# MSS_PKA register map
Vendor: Texas Instruments
Peripheral module from a debugger description file (folder radar).
Registers are 32-bit, access per field, no defined reset value unless marked. A register's access mark holds for its fields unless they carry their own. Offsets are as the file gives them; lines under a group give offsets from that group; [hi:lo] are bit positions; {n}, {i} and the like mark numbered series; 'fields as' and 'values as' point back to an identical list; <NAME> marks a mode.

## MSS_PKA
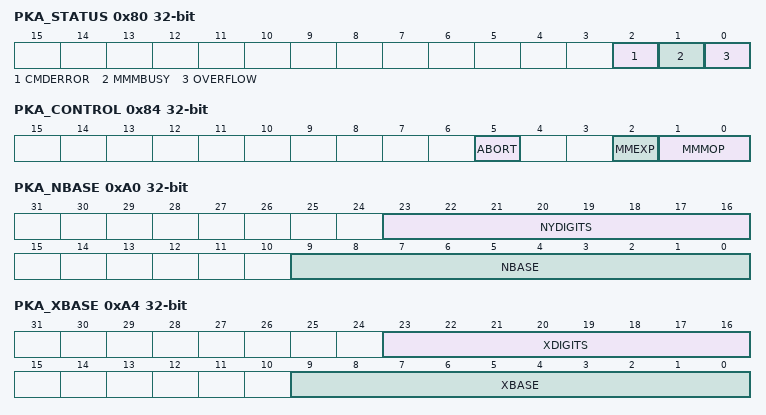
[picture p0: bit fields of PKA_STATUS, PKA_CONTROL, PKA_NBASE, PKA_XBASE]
0x80 PKA_STATUS
  [2] CMDERROR rw — Set to ‘1’ by pkaeip29t when trying to start multiple operations in one command automatically cleared to ‘0’ by hardware on start of any (legal) operation.
  [1] MMMBUSY rw — Set to ‘1’ by pkaeip29t when the LNME executes an MMM MMMNEXT MMM3A or MMEXP operation (cannot be written to ‘0’ during execution of this operation). Automatically cleared to ‘0’ by pkaeip29t on finish of an operation. The interrupt output is the complement of this bit and can be controlled directly for testing purposes when no actual operation is busy.
  [0] OVERFLOW rw — Set to ‘1’ by pkaeip29t when the result of MMM MMMNEXT MMM3A or MMEXP operation is equal or greater than the modulus N. Updated at the end of an operation automatically cleared to ‘0’ by pkaeip29t on start of any operation.
0x84 PKA_CONTROL
  [5] ABORT rw — Set to ‘1’ the pkaeip29t is reset and all internal storage locations are flushed within 200 clock cycles is cleared to ‘0’ by hardware at the end of the operation. This command has priority over the MMM MMMNEXT MMM3A and MMEXP commands and can abort those in mid-execution. 0 No operation 1 abort
  [2] MMEXP rw — The pkaeip29t starts an MMEXP operation bit is cleared to ‘0’ by pkaeip29t at the end of the operation or when executing an ABORT command. 0 No operation. 1 Starts an MMEXP operation.
  [1:0] MMMOP rw — When set to a non-zero value the pkaeip29t starts an MMM operation cleared to ‘00’ by hardware at the end of the operation or when executing an ABORT command: 0x0 No operation 0x1 Starts a basic MMM operation (result written over the Y operand vector) 0x2 Starts an MMMNEXT operation (result written following the Y operand) 0x3 Starts an MMM3A operation (result written at the B operand address)
0xA0 PKA_NBASE
  [23:16] NYDIGITS rw — Y-Operand and N-Operand 32-bit Digits. Also used for X-operand length in an MMEXP operation. Minimum value is 0 (for 32-bit operands) maximum value is 66 (for 2112-bit operands actually 2112 ‘real’ data bits plus 32 bits to handle inputs and results higher than the 2112 bits modulus value).
  [9:0] NBASE rw — N-Operand Base Address. Bit [0] is forced to ‘0’ to locate the first 32-bit word at a 64-bit word boundary.
0xA4 PKA_XBASE
  [23:16] XDIGITS rw — X-Operand 32-bit Digits used for MMM MMMNEXT and MMM3A operations only. Minimum value is 0 (for 32-bit X operands) maximum value is 66 (for 2114-bit X operands actually 2112 ‘real’ data bits plus 2 extra bits to handle X inputs up to four times the 2112-bit modulus value plus 30 dummy data bits to fill out the last word which should all be 0).
  [9:0] XBASE rw — X-Operand Base Address. Bit [0] is forced to ‘0’ to locate the first 32-bit word at a 64-bit word boundary.
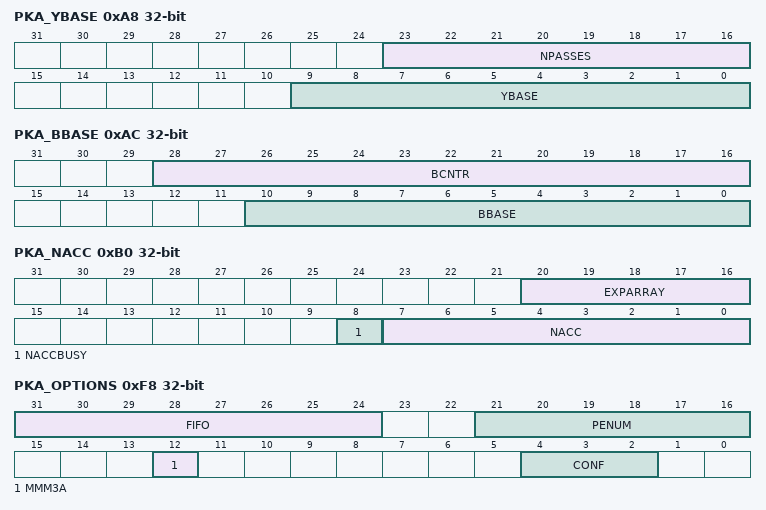
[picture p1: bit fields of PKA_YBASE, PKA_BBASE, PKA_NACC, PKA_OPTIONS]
0xA8 PKA_YBASE
  [23:16] NPASSES rw — MMM Passes. Minimum value is 0 (for ONE pass) maximum value is 255 for 256 passes.
  [9:0] YBASE rw — Y-Operand Base Address. Bit [0] is forced to ‘0’ to locate the first 32-bit word at a 64-bit word boundary.
0xAC PKA_BBASE
  [28:16] BCNTR rw — B-Operand Bit Count. Minimum value is 0 for an exponent length of 2 bits; maximum value is 2111 for an exponent of 2113 bits (to allow exponent blinding). If no exponent blinding is used the exponent would normally be smaller than the modulus. Note that the most significant B operand bit need not be stored in memory and is always assumed to be ‘1’.
  [10:0] BBASE rw — B-Operand BASE Address. Bit [0] is forced to ‘0’ to locate the first 32-bit word at a 64-bit word boundary.
0xB0 PKA_NACC
  [20:16] EXPARRAY rw — Exponent Array size (used for MMEXP operations only). A minimum (default) value of 0 indicates that there is only one "odd power": AR mod N. This is the value of EXPARRAY when exponent re-coding is not used. A maximum value of 31 indicates 32 odd powers can be used for exponent recoding; this includes A1R mod N as the first “odd power”.
  [8] NACCBUSY rw — NACC Calculation Busy set high during 8 clock cycles after writing NZERO in PKA_NZERO while NACC is being calculated. During this time operation starts are stalled. Writing this bit with ‘0’ aborts the calculation but can leave NACC in an unknown state (writing NACC while resetting NACC_BUSY prevents this).
  [7:0] NACC rw — N Accent. Any odd8 bits value (bit [0] is ‘1’) can be loaded here (result of calculation). Automatically loaded with calculated value after writing NZERO in PKA_NZERO register.
0xB4 PKA_NZERO
  [7:0] NZERO rw — N vector byte 0. Any odd 8 bit value (bit [0] is ‘1’) can be loaded here. Writing starts the NACC calculation automatically.
0xF8 PKA_OPTIONS ro
  [31:24] FIFO — Number of words in the LNME unit’s FIFO RAM. Default is value 70.
  [21:16] PENUM — Number of Processing Elements in the pipeline of the LNME unit. Default is value 6.
  [12] MMM3A — Value ‘1’ indicates the 3-address MMM3A function is implemented.
  [4:2] CONF — Value 1 indicates one standard LNME unit (with alpha = 32 beta = 8) other values reserved.
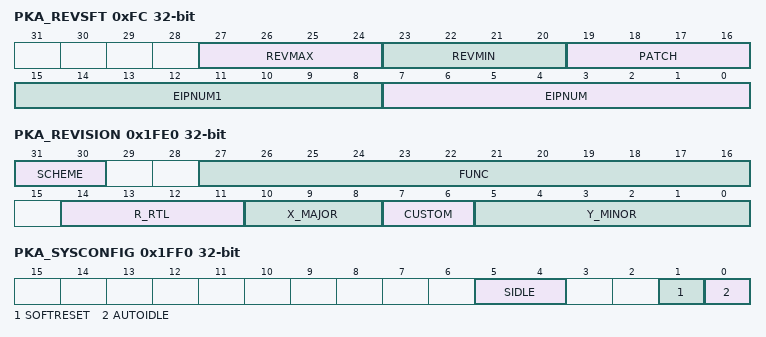
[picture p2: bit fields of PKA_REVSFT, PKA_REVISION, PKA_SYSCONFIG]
0xFC PKA_REVSFT ro
  [27:24] REVMAX — 4-bit binary encoding of the major hardware revision number.
  [23:20] REVMIN — 4-bit binary encoding of the minor hardware revision number.
  [19:16] PATCH — 4-bit binary encoding of the hardware patch level.
  [15:8] EIPNUM1 — Bit-by-bit logic complement of bits [7:0].
  [7:0] EIPNUM — 8 bits binary encoding of the EIP number.
0x1FE0 PKA_REVISION ro
  [31:30] SCHEME — Used to distinguish between old scheme and current. Read�0x0 Legacy ASP or WTBU scheme Read�0x1 Highlander 0.8 scheme
  [27:16] FUNC — Function indicates a software compatible module family. If there is no level of software compatibility a new Func number (and hence REVISION) should be assigned.
  [14:11] R_RTL — RTL Version (R) maintained by IP design owner. RTL follows a numbering such as X.Y.R.Z which are explained in this table. R changes ONLY when: (1) PDS uploads occur which may have been due to spec changes (2) Bug fixes occur (3) Resets to '0' when X or Y changes. Design team has an internal 'Z' (customer invisible) number which increments on every drop that happens due to DV and RTL updates. Z resets to 0 when R increments.
  [10:8] X_MAJOR — Major Revision (X) maintained by IP specification owner. X changes ONLY when: (1) There is a major feature addition. An example would be adding Master Mode to Utopia Level2. The Func field (or Class/Type in old PID format) will remain the same. X does NOT change due to: (1) Bug fixes (2) Change in feature parameters.
  [7:6] CUSTOM — Indicates a special version for a particular device. Consequence of use may avoid use of standard Chip Support Library (CSL) / Drivers. Read�0x0 Non custom (standard) revision
  [5:0] Y_MINOR — Minor Revision (Y) maintained by IP specification owner. Y changes ONLY when: (1) Features are scaled (up or down). Flexibility exists in that this feature scalability may either be represented in the Y change or a specific register in the IP that indicates which features are exactly available. (2) When feature creeps from Is-Not list to Is list. But this may not be the case once it sees silicon; in which case X will change. Y does NOT change due to: (1) Bug fixes (2) Typos or clarifications (3) major functional/feature change/addition/deletion. Instead these changes may be reflected via R S X as applicable. Spec owner maintains a customer-invisible number 'S' which changes due to: (1) Typos/clarifications (2) Bug documentation. Note that this bug is not due to a spec change but due to implementation. Nevertheless the spec tracks the IP bugs. An RTL release (say for silicon PG1.1) that occurs due to bug fix should document the corresponding spec number (X.Y.S) in its release notes.
0x1FF0 PKA_SYSCONFIG
  [5:4] SIDLE rw — sidle mode 0x0 Force Idle mode. 0x1 No idle 0x2 Smart Idle mode 0x3 reserved
  [1] SOFTRESET rw — softreset 0 No operation. 1 When '1' starts softreset sequnce.
  [0] AUTOIDLE rw — autoidle 0 When '0' internal clocks are running. 1 When '1' internal clocks are cut.
0x1FF4 PKA_SYSSTATUS ro
  [0] RESETDONE
0x1FF8 PKA_IRQSTATUS ro
  [0] PKAIRQSTAT — Interrupt flag
0x1FFC PKA_IRQENABLE
  [0] PKAIRQEN rw — data 0 Disable the interrupt 1 Enable the interrupt
0x2000 PKA_RAM_START rw
  [31:0] DATARAM — data
0x2FFC PKA_RAM_END rw
  [31:0] DATARAM — data
